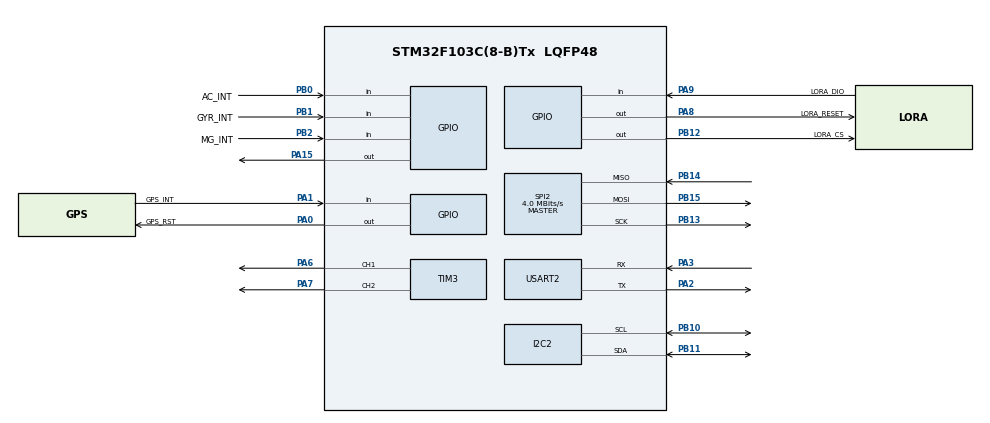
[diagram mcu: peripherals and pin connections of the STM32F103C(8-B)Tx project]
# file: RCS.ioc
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Mcu.Family=STM32F1
Mcu.Name=STM32F103C(8-B)Tx
Mcu.Package=LQFP48
NVIC.PriorityGroup=NVIC_PRIORITYGROUP_4
PA0-WKUP.GPIO_Label=GPS_RST
PA0-WKUP.Signal=GPIO_Output
PA1.GPIO_Label=GPS_INT
PA1.Signal=GPIO_Input
PA13.Mode=Serial_Wire
PA13.Signal=SYS_JTMS-SWDIO
PA14.Mode=Serial_Wire
PA14.Signal=SYS_JTCK-SWCLK
PA15.Signal=GPIO_Output
PA2.Mode=Asynchronous
PA2.Signal=USART2_TX
PA3.Mode=Asynchronous
PA3.Signal=USART2_RX
PA6.Signal=S_TIM3_CH1
PA7.Signal=S_TIM3_CH2
PA8.GPIO_Label=LORA_RESET
PA8.Signal=GPIO_Output
PA9.GPIO_Label=LORA_DIO
PA9.Signal=GPIO_Input
PB0.GPIO_Label=AC_INT
PB0.Signal=GPIO_Input
PB1.GPIO_Label=GYR_INT
PB1.Signal=GPIO_Input
PB10.Mode=I2C
PB10.Signal=I2C2_SCL
PB11.Mode=I2C
PB11.Signal=I2C2_SDA
PB12.GPIO_Label=LORA_CS
PB12.Signal=GPIO_Output
PB13.Mode=Full_Duplex_Master
PB13.Signal=SPI2_SCK
PB14.Mode=Full_Duplex_Master
PB14.Signal=SPI2_MISO
PB15.Mode=Full_Duplex_Master
PB15.Signal=SPI2_MOSI
PB2.GPIO_Label=MG_INT
PB2.Signal=GPIO_Input
ProjectManager.HeapSize=0x200
ProjectManager.StackSize=0x400
ProjectManager.TargetToolchain=STM32CubeIDE
RCC.APB1Freq_Value=8000000
RCC.APB2Freq_Value=8000000
SH.S_TIM3_CH1.0=TIM3_CH1,PWM Generation1 CH1
SH.S_TIM3_CH2.0=TIM3_CH2,PWM Generation2 CH2
SPI2.CalculateBaudRate=4.0 MBits/s
SPI2.Direction=SPI_DIRECTION_2LINES
SPI2.Mode=SPI_MODE_MASTER
SPI2.VirtualType=VM_MASTER
TIM3.Channel-PWM\ Generation1\ CH1=TIM_CHANNEL_1
TIM3.Channel-PWM\ Generation2\ CH2=TIM_CHANNEL_2
TIM3.Pulse-PWM\ Generation1\ CH1=10000
TIM3.Pulse-PWM\ Generation2\ CH2=15000
USART2.VirtualMode=VM_ASYNC
board=custom

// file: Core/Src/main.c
/* USER CODE BEGIN Header */
/**
  ******************************************************************************
  * @file           : main.c
  * @brief          : Main program body
  ******************************************************************************
  * @attention
  *
  * <h2><center>&copy; Copyright (c) 2023 STMicroelectronics.
  * All rights reserved.</center></h2>
  *
  * This software component is licensed by ST under BSD 3-Clause license,
  * the "License"; You may not use this file except in compliance with the
  * License. You may obtain a copy of the License at:
  *                        opensource.org/licenses/BSD-3-Clause
  *
  ******************************************************************************
  */
/* USER CODE END Header */
#include "main.h"
#include "i2c.h"
#include "spi.h"
#include "tim.h"
#include "usart.h"
#include "gpio.h"

/* USER CODE BEGIN PD */
#define MAG_ADR 0x0F
#define MAG_ID_REG 0x00
/* USER CODE END PD */

void SystemClock_Config(void);

int main(void)
{

  /* MCU Configuration--------------------------------------------------------*/

  /* Reset of all peripherals, Initializes the Flash interface and the Systick. */
  HAL_Init();

  /* Configure the system clock */
  SystemClock_Config();

  /* Initialize all configured peripherals */
  MX_GPIO_Init();
  MX_SPI2_Init();
  MX_USART2_UART_Init();
  MX_TIM3_Init();
  MX_I2C2_Init();
  /* USER CODE BEGIN 2 */

  uint8_t buffer;
  buffer = 0;
 // if(ret != HAL_OK){
//	  x=0;
 // }
  /* USER CODE END 2 */

  /* Infinite loop */
  /* USER CODE BEGIN WHILE */
  while (1)
  {
	  HAL_GPIO_WritePin(LORA_RESET_GPIO_Port, LORA_RESET_Pin, GPIO_PIN_RESET);
	     HAL_Delay(100);
	     HAL_GPIO_WritePin(LORA_RESET_GPIO_Port, LORA_RESET_Pin, GPIO_PIN_SET);

	     HAL_SPI_Transmit(&hspi2, (uint8_t *)0x0E, 1, 100);
	     HAL_SPI_Receive(&hspi2, (uint8_t *)buffer, 1, 100);
	     HAL_Delay(1000);
    /* USER CODE END WHILE */

  }
}

void SystemClock_Config(void)
{
  RCC_OscInitTypeDef RCC_OscInitStruct = {0};
  RCC_ClkInitTypeDef RCC_ClkInitStruct = {0};

  /** Initializes the RCC Oscillators according to the specified parameters
  * in the RCC_OscInitTypeDef structure.
  */
  RCC_OscInitStruct.OscillatorType = RCC_OSCILLATORTYPE_HSI;
  RCC_OscInitStruct.HSIState = RCC_HSI_ON;
  RCC_OscInitStruct.HSICalibrationValue = RCC_HSICALIBRATION_DEFAULT;
  RCC_OscInitStruct.PLL.PLLState = RCC_PLL_NONE;
  if (HAL_RCC_OscConfig(&RCC_OscInitStruct) != HAL_OK)
  {
    Error_Handler();
  }
  /** Initializes the CPU, AHB and APB buses clocks
  */
  RCC_ClkInitStruct.ClockType = RCC_CLOCKTYPE_HCLK|RCC_CLOCKTYPE_SYSCLK
                              |RCC_CLOCKTYPE_PCLK1|RCC_CLOCKTYPE_PCLK2;
  RCC_ClkInitStruct.SYSCLKSource = RCC_SYSCLKSOURCE_HSI;
  RCC_ClkInitStruct.AHBCLKDivider = RCC_SYSCLK_DIV1;
  RCC_ClkInitStruct.APB1CLKDivider = RCC_HCLK_DIV1;
  RCC_ClkInitStruct.APB2CLKDivider = RCC_HCLK_DIV1;

  if (HAL_RCC_ClockConfig(&RCC_ClkInitStruct, FLASH_LATENCY_0) != HAL_OK)
  {
    Error_Handler();
  }
}

void Error_Handler(void)
{
}

/************************ (C) COPYRIGHT STMicroelectronics *****END OF FILE****/
